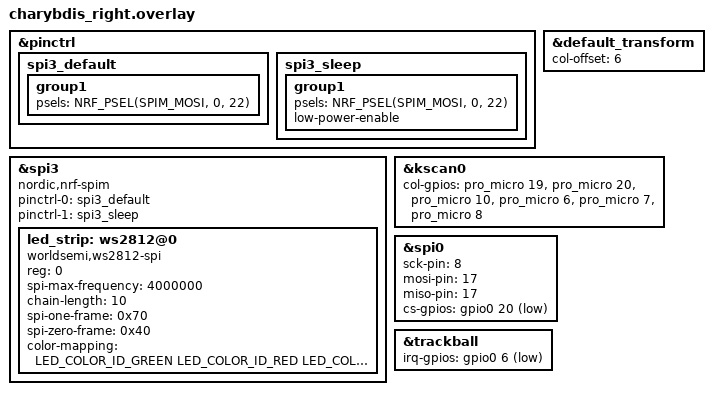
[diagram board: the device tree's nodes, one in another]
/*
 * Copyright (c) 2020 ZMK Contributors
 *
 * SPDX-License-Identifier: MIT
 */
 
#include "charybdis.dtsi"




#include <dt-bindings/led/led.h>

&pinctrl {
    spi3_default: spi3_default {
        group1 {
            psels = <NRF_PSEL(SPIM_MOSI, 0, 22)>;
        };
    };

    spi3_sleep: spi3_sleep {
        group1 {
            psels = <NRF_PSEL(SPIM_MOSI, 0, 22)>;
            low-power-enable;
        };
    };
};

&spi3 {
  compatible = "nordic,nrf-spim";
  status = "okay";

  pinctrl-0 = <&spi3_default>;
  pinctrl-1 = <&spi3_sleep>;
  pinctrl-names = "default", "sleep";

  led_strip: ws2812@0 {
    compatible = "worldsemi,ws2812-spi";

    /* SPI */
    reg = <0>; /* ignored, but necessary for SPI bindings */
    spi-max-frequency = <4000000>;

    /* WS2812 */
    chain-length = <10>; /* number of LEDs */
    spi-one-frame = <0x70>;
    spi-zero-frame = <0x40>;
    color-mapping = <LED_COLOR_ID_GREEN
                          LED_COLOR_ID_RED
                          LED_COLOR_ID_BLUE>;
  };
};






&default_transform {
    col-offset = <6>;
};

&kscan0 {
	col-gpios
		= <&pro_micro 19 (GPIO_ACTIVE_HIGH | GPIO_PULL_DOWN)>
		, <&pro_micro 20 (GPIO_ACTIVE_HIGH | GPIO_PULL_DOWN)>
		, <&pro_micro 10 (GPIO_ACTIVE_HIGH | GPIO_PULL_DOWN)>
		, <&pro_micro 6 (GPIO_ACTIVE_HIGH | GPIO_PULL_DOWN)>
		, <&pro_micro 7 (GPIO_ACTIVE_HIGH | GPIO_PULL_DOWN)>
		, <&pro_micro 8 (GPIO_ACTIVE_HIGH | GPIO_PULL_DOWN)>
		;
};

// trackball bus
&spi0 {
	status = "okay"; //okay
	sck-pin = <8>;
	mosi-pin = <17>;
	miso-pin = <17>; // same as mosi (3-wire spi)
	cs-gpios = <&gpio0 20 GPIO_ACTIVE_LOW>;
};

&trackball {
	status = "okay"; //okay
	irq-gpios = <&gpio0 6 (GPIO_ACTIVE_LOW | GPIO_PULL_UP)>;
};
